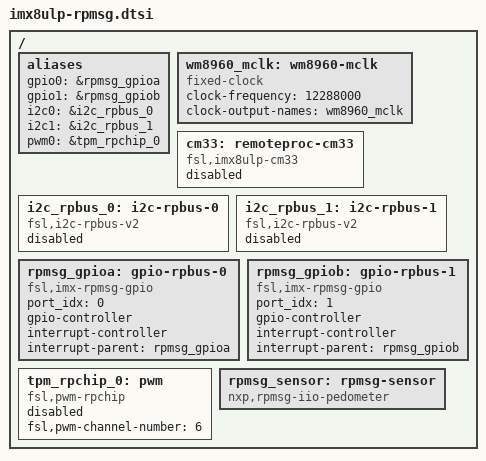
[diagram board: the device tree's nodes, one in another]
// SPDX-License-Identifier: (GPL-2.0+ OR MIT)
/*
 * Copyright 2021 NXP
 */

/ {
	aliases {
		gpio0 = &rpmsg_gpioa;
		gpio1 = &rpmsg_gpiob;
		i2c0 = &i2c_rpbus_0;
		i2c1 = &i2c_rpbus_1;
		pwm0 = &tpm_rpchip_0;
	};

	wm8960_mclk: wm8960-mclk {
		compatible = "fixed-clock";
		clock-frequency = <12288000>;
		clock-output-names = "wm8960_mclk";
		#clock-cells = <0>;
	};

	cm33: remoteproc-cm33 {
		compatible = "fsl,imx8ulp-cm33";
		status = "disabled";
	};

	i2c_rpbus_0: i2c-rpbus-0 {
		compatible = "fsl,i2c-rpbus-v2";
		status = "disabled";
	};

	i2c_rpbus_1: i2c-rpbus-1 {
		compatible = "fsl,i2c-rpbus-v2";
		status = "disabled";
	};

	rpmsg_gpioa: gpio-rpbus-0 {
		compatible = "fsl,imx-rpmsg-gpio";
		port_idx = <0>;
		gpio-controller;
		#gpio-cells = <2>;
		#interrupt-cells = <2>;
		interrupt-controller;
		interrupt-parent = <&rpmsg_gpioa>;
		status = "okay";
	};

	rpmsg_gpiob: gpio-rpbus-1 {
		compatible = "fsl,imx-rpmsg-gpio";
		port_idx = <1>;
		gpio-controller;
		#gpio-cells = <2>;
		#interrupt-cells = <2>;
		interrupt-controller;
		interrupt-parent = <&rpmsg_gpiob>;
		status = "okay";
	};

	tpm_rpchip_0: pwm {
		compatible = "fsl,pwm-rpchip";
		#pwm-cells = <3>;
		fsl,pwm-channel-number = <6>;
		status = "disabled";
	};

	rpmsg_sensor: rpmsg-sensor {
		compatible = "nxp,rpmsg-iio-pedometer";
		status = "okay";
	};
};
